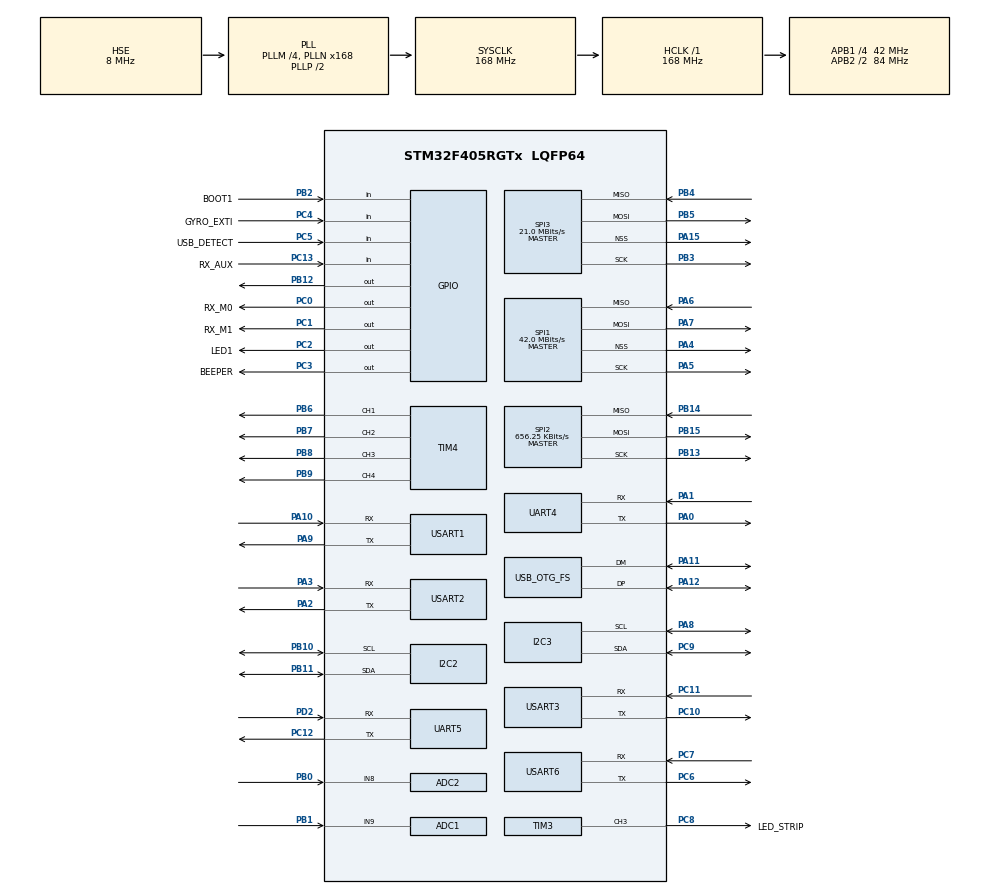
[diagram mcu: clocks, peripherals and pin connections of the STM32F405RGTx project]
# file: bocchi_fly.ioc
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ADC1.Channel-1\#ChannelRegularConversion=ADC_CHANNEL_9
ADC1.NbrOfConversionFlag=1
ADC1.Rank-1\#ChannelRegularConversion=1
ADC1.SamplingTime-1\#ChannelRegularConversion=ADC_SAMPLETIME_3CYCLES
ADC1.master=1
ADC2.Channel-1\#ChannelRegularConversion=ADC_CHANNEL_8
ADC2.NbrOfConversionFlag=1
ADC2.Rank-1\#ChannelRegularConversion=1
ADC2.SamplingTime-1\#ChannelRegularConversion=ADC_SAMPLETIME_3CYCLES
Mcu.Family=STM32F4
Mcu.Name=STM32F405RGTx
Mcu.Package=LQFP64
NVIC.PriorityGroup=NVIC_PRIORITYGROUP_4
PA0-WKUP.Mode=Asynchronous
PA0-WKUP.Signal=UART4_TX
PA1.Mode=Asynchronous
PA1.Signal=UART4_RX
PA10.Mode=Asynchronous
PA10.Signal=USART1_RX
PA11.Mode=Device_Only
PA11.Signal=USB_OTG_FS_DM
PA12.Mode=Device_Only
PA12.Signal=USB_OTG_FS_DP
PA13.Mode=Serial_Wire
PA13.Signal=SYS_JTMS-SWDIO
PA14.Mode=Serial_Wire
PA14.Signal=SYS_JTCK-SWCLK
PA15.Mode=NSS_Signal_Hard_Output
PA15.Signal=SPI3_NSS
PA2.Mode=Asynchronous
PA2.Signal=USART2_TX
PA3.Mode=Asynchronous
PA3.Signal=USART2_RX
PA4.Mode=NSS_Signal_Hard_Output
PA4.Signal=SPI1_NSS
PA5.Mode=Full_Duplex_Master
PA5.Signal=SPI1_SCK
PA6.Mode=Full_Duplex_Master
PA6.Signal=SPI1_MISO
PA7.Mode=Full_Duplex_Master
PA7.Signal=SPI1_MOSI
PA8.Mode=I2C
PA8.Signal=I2C3_SCL
PA9.Mode=Asynchronous
PA9.Signal=USART1_TX
PB0.Signal=ADCx_IN8
PB1.Signal=ADCx_IN9
PB10.Mode=I2C
PB10.Signal=I2C2_SCL
PB11.Mode=I2C
PB11.Signal=I2C2_SDA
PB12.GPIO_PuPd=GPIO_PULLUP
PB12.Signal=GPIO_Output
PB13.GPIO_PuPd=GPIO_PULLUP
PB13.Mode=Full_Duplex_Master
PB13.Signal=SPI2_SCK
PB14.Mode=Full_Duplex_Master
PB14.Signal=SPI2_MISO
PB15.Mode=Full_Duplex_Master
PB15.Signal=SPI2_MOSI
PB2.GPIO_Label=BOOT1
PB2.Signal=GPIO_Input
PB3.Mode=Full_Duplex_Master
PB3.Signal=SPI3_SCK
PB4.Mode=Full_Duplex_Master
PB4.Signal=SPI3_MISO
PB5.Mode=Full_Duplex_Master
PB5.Signal=SPI3_MOSI
PB6.Signal=S_TIM4_CH1
PB7.Signal=S_TIM4_CH2
PB8.Signal=S_TIM4_CH3
PB9.Signal=S_TIM4_CH4
PC0.GPIO_Label=RX_M0
PC0.Signal=GPIO_Output
PC1.GPIO_Label=RX_M1
PC1.Signal=GPIO_Output
PC10.Mode=Asynchronous
PC10.Signal=USART3_TX
PC11.Mode=Asynchronous
PC11.Signal=USART3_RX
PC12.Mode=Asynchronous
PC12.Signal=UART5_TX
PC13-ANTI_TAMP.GPIO_Label=RX_AUX
PC13-ANTI_TAMP.Signal=GPIO_Input
PC2.GPIO_Label=LED1
PC2.Signal=GPIO_Output
PC3.GPIO_Label=BEEPER
PC3.Signal=GPIO_Output
PC4.GPIO_Label=GYRO_EXTI
PC4.Signal=GPIO_Input
PC5.GPIO_Label=USB_DETECT
PC5.Signal=GPIO_Input
PC6.Mode=Asynchronous
PC6.Signal=USART6_TX
PC7.Mode=Asynchronous
PC7.Signal=USART6_RX
PC8.GPIO_Label=LED_STRIP
PC8.Signal=S_TIM3_CH3
PC9.Mode=I2C
PC9.Signal=I2C3_SDA
PD2.Mode=Asynchronous
PD2.Signal=UART5_RX
PH0-OSC_IN.Mode=HSE-External-Oscillator
PH0-OSC_IN.Signal=RCC_OSC_IN
PH1-OSC_OUT.Mode=HSE-External-Oscillator
PH1-OSC_OUT.Signal=RCC_OSC_OUT
ProjectManager.HeapSize=0x200
ProjectManager.StackSize=0x400
ProjectManager.TargetToolchain=Makefile
RCC.48MHZClocksFreq_Value=48000000
RCC.AHBFreq_Value=168000000
RCC.APB1CLKDivider=RCC_HCLK_DIV4
RCC.APB1Freq_Value=42000000
RCC.APB1TimFreq_Value=84000000
RCC.APB2CLKDivider=RCC_HCLK_DIV2
RCC.APB2Freq_Value=84000000
RCC.APB2TimFreq_Value=168000000
RCC.CortexFreq_Value=168000000
RCC.HCLKFreq_Value=168000000
RCC.HSE_VALUE=8000000
RCC.HSI_VALUE=16000000
RCC.LSE_VALUE=32768
RCC.PLLM=4
RCC.PLLN=168
RCC.PLLQ=7
RCC.SYSCLKFreq_VALUE=168000000
RCC.SYSCLKSource=RCC_SYSCLKSOURCE_PLLCLK
RCC.VCOOutputFreq_Value=336000000
SH.ADCx_IN8.0=ADC2_IN8,IN8
SH.ADCx_IN9.0=ADC1_IN9,IN9
SH.S_TIM3_CH3.0=TIM3_CH3,PWM Generation3 CH3
SH.S_TIM4_CH1.0=TIM4_CH1,PWM Generation1 CH1
SH.S_TIM4_CH2.0=TIM4_CH2,PWM Generation2 CH2
SH.S_TIM4_CH3.0=TIM4_CH3,PWM Generation3 CH3
SH.S_TIM4_CH4.0=TIM4_CH4,PWM Generation4 CH4
SPI1.CalculateBaudRate=42.0 MBits/s
SPI1.Direction=SPI_DIRECTION_2LINES
SPI1.Mode=SPI_MODE_MASTER
SPI1.VirtualNSS=VM_NSSHARD
SPI1.VirtualType=VM_MASTER
SPI2.BaudRatePrescaler=SPI_BAUDRATEPRESCALER_64
SPI2.CalculateBaudRate=656.25 KBits/s
SPI2.Direction=SPI_DIRECTION_2LINES
SPI2.Mode=SPI_MODE_MASTER
SPI2.VirtualType=VM_MASTER
SPI3.CalculateBaudRate=21.0 MBits/s
SPI3.Direction=SPI_DIRECTION_2LINES
SPI3.Mode=SPI_MODE_MASTER
SPI3.VirtualNSS=VM_NSSHARD
SPI3.VirtualType=VM_MASTER
TIM3.Channel-PWM\ Generation3\ CH3=TIM_CHANNEL_3
TIM4.Channel-PWM\ Generation1\ CH1=TIM_CHANNEL_1
TIM4.Channel-PWM\ Generation2\ CH2=TIM_CHANNEL_2
TIM4.Channel-PWM\ Generation3\ CH3=TIM_CHANNEL_3
TIM4.Channel-PWM\ Generation4\ CH4=TIM_CHANNEL_4
UART4.VirtualMode=Asynchronous
UART5.VirtualMode=Asynchronous
USART1.VirtualMode=VM_ASYNC
USART2.VirtualMode=VM_ASYNC
USART3.VirtualMode=VM_ASYNC
USART6.VirtualMode=VM_ASYNC
USB_OTG_FS.VirtualMode=Device_Only
VP_TIM3_VS_ClockSourceINT.Mode=Internal
VP_TIM4_VS_ClockSourceINT.Mode=Internal
board=custom

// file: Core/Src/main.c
/* USER CODE BEGIN Header */
/**
  ******************************************************************************
  * @file           : main.c
  * @brief          : Main program body
  ******************************************************************************
  * @attention
  *
  * Copyright (c) 2025 STMicroelectronics.
  * All rights reserved.
  *
  * This software is licensed under terms that can be found in the LICENSE file
  * in the root directory of this software component.
  * If no LICENSE file comes with this software, it is provided AS-IS.
  *
  ******************************************************************************
  */
/* USER CODE END Header */
#include "main.h"
#include "adc.h"
#include "i2c.h"
#include "spi.h"
#include "tim.h"
#include "usart.h"
#include "usb_otg.h"
#include "gpio.h"

/* USER CODE BEGIN Includes */
#include "test/mpu6500_test.h"
#include "drivers/mpu6500.h"
/* USER CODE END Includes */

void SystemClock_Config(void);

int main(void)
{

    /* MCU Configuration--------------------------------------------------------*/

    /* Reset of all peripherals, Initializes the Flash interface and the Systick. */
    HAL_Init();

    /* Configure the system clock */
    SystemClock_Config();

    /* Initialize all configured peripherals */
    MX_GPIO_Init();
    MX_TIM3_Init();
    MX_ADC1_Init();
    MX_ADC2_Init();
    MX_I2C2_Init();
    MX_I2C3_Init();
    MX_SPI1_Init();
    MX_SPI2_Init();
    MX_SPI3_Init();
    MX_TIM4_Init();
    MX_UART4_Init();
    MX_UART5_Init();
    MX_USART1_UART_Init();
    MX_USART2_UART_Init();
    MX_USART3_UART_Init();
    MX_USART6_UART_Init();
    MX_USB_OTG_FS_PCD_Init();
    /* USER CODE BEGIN 2 */

    // mpu6500_sensor_data_test();
    Euler_angles_test();
    /* USER CODE END 2 */

    /* Infinite loop */
    /* USER CODE BEGIN WHILE */
    while (1)
    {
        HAL_Delay(1000);
        /* USER CODE END WHILE */

    }
}

void SystemClock_Config(void)
{
    RCC_OscInitTypeDef RCC_OscInitStruct = {0};
    RCC_ClkInitTypeDef RCC_ClkInitStruct = {0};

    /** Configure the main internal regulator output voltage
    */
    __HAL_RCC_PWR_CLK_ENABLE();
    __HAL_PWR_VOLTAGESCALING_CONFIG(PWR_REGULATOR_VOLTAGE_SCALE1);

    /** Initializes the RCC Oscillators according to the specified parameters
    * in the RCC_OscInitTypeDef structure.
    */
    RCC_OscInitStruct.OscillatorType = RCC_OSCILLATORTYPE_HSE;
    RCC_OscInitStruct.HSEState = RCC_HSE_ON;
    RCC_OscInitStruct.PLL.PLLState = RCC_PLL_ON;
    RCC_OscInitStruct.PLL.PLLSource = RCC_PLLSOURCE_HSE;
    RCC_OscInitStruct.PLL.PLLM = 4;
    RCC_OscInitStruct.PLL.PLLN = 168;
    RCC_OscInitStruct.PLL.PLLP = RCC_PLLP_DIV2;
    RCC_OscInitStruct.PLL.PLLQ = 7;
    if (HAL_RCC_OscConfig(&RCC_OscInitStruct) != HAL_OK)
    {
        Error_Handler();
    }

    /** Initializes the CPU, AHB and APB buses clocks
    */
    RCC_ClkInitStruct.ClockType = RCC_CLOCKTYPE_HCLK|RCC_CLOCKTYPE_SYSCLK
                                  |RCC_CLOCKTYPE_PCLK1|RCC_CLOCKTYPE_PCLK2;
    RCC_ClkInitStruct.SYSCLKSource = RCC_SYSCLKSOURCE_PLLCLK;
    RCC_ClkInitStruct.AHBCLKDivider = RCC_SYSCLK_DIV1;
    RCC_ClkInitStruct.APB1CLKDivider = RCC_HCLK_DIV4;
    RCC_ClkInitStruct.APB2CLKDivider = RCC_HCLK_DIV2;

    if (HAL_RCC_ClockConfig(&RCC_ClkInitStruct, FLASH_LATENCY_5) != HAL_OK)
    {
        Error_Handler();
    }
}

void Error_Handler(void)
{
    __disable_irq();
    while (1)
    {
    }
}
